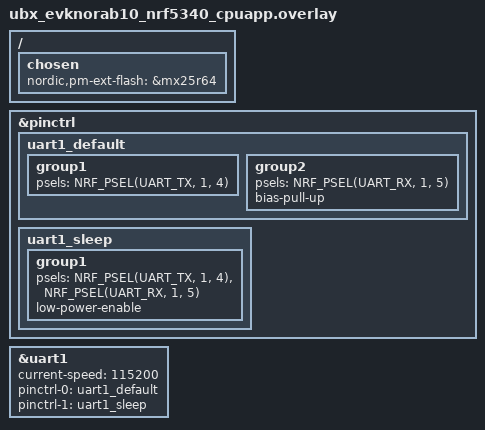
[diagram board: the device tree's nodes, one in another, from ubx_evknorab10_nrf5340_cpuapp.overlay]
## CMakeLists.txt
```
# SPDX-License-Identifier: Apache-2.0

cmake_minimum_required(VERSION 3.20.0)

find_package(Zephyr REQUIRED HINTS $ENV{ZEPHYR_BASE})
if (NOT SYSBUILD)
	message(WARNING
		" This is multi-image application that should be build using sysbuild.\n"
		" Add --sysbuild argument to west build command to prepare all the images.")
endif()
project(hrdfu)

target_sources(app PRIVATE src/main.c)
add_subdirectory(src/storage)
add_subdirectory(src/uart)
```

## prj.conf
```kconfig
CONFIG_BT=y
CONFIG_LOG=y
CONFIG_BT_SMP=y
CONFIG_BT_PERIPHERAL=y
CONFIG_BT_DIS=y
CONFIG_BT_DIS_PNP=n
CONFIG_BT_BAS=y
CONFIG_BT_HRS=y
CONFIG_BT_DEVICE_NAME="Zephyr Heartrate Sensor"
CONFIG_BT_DEVICE_APPEARANCE=833

CONFIG_SYSTEM_WORKQUEUE_STACK_SIZE=4096
CONFIG_MAIN_STACK_SIZE=8192

#-------------------------------------------------
CONFIG_MULTITHREADING=y
CONFIG_LOG_MODE_MINIMAL=n # former CONFIG_MODE_MINIMAL

CONFIG_LOG=y
CONFIG_PRINTK=y

# Config RTT logger
# CONFIG_CONSOLE=y
# CONFIG_UART_CONSOLE=n
# CONFIG_RTT_CONSOLE=y
# CONFIG_USE_SEGGER_RTT=y
# CONFIG_LOG_BACKEND_RTT=y
#----------------------------------------------------------
CONFIG_BOOTLOADER_MCUBOOT=y
CONFIG_NCS_SAMPLE_MCUMGR_BT_OTA_DFU=y

# #-------------------------------------------------
CONFIG_NRF53_UPGRADE_NETWORK_CORE=y
CONFIG_PM_EXTERNAL_FLASH_MCUBOOT_SECONDARY=y
CONFIG_UPDATEABLE_IMAGE_NUMBER=2
CONFIG_IMG_ERASE_PROGRESSIVELY=y

#-------------------------------------------------
CONFIG_SPI=y
CONFIG_NORDIC_QSPI_NOR=y
# Enable flash operations.
CONFIG_FLASH=y
CONFIG_FLASH_MAP=y
CONFIG_FLASH_PAGE_LAYOUT=y
CONFIG_STREAM_FLASH=y


# # Enable the LittleFS file system.
CONFIG_FILE_SYSTEM=y
CONFIG_FILE_SYSTEM_LITTLEFS=y

CONFIG_SERIAL=y
CONFIG_UART_INTERRUPT_DRIVEN=y
```

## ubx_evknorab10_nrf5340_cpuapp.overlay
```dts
// To get started, press Ctrl+Space to bring up the completion menu and view the available nodes.

// You can also use the buttons in the sidebar to perform actions on nodes.
// Actions currently available include:

// * Enabling / disabling the node
// * Adding the bus to a bus
// * Removing the node
// * Connecting ADC channels

// For more help, browse the DeviceTree documentation at https://docs.zephyrproject.org/latest/guides/dts/index.html
// You can also visit the nRF DeviceTree extension documentation at https://nrfconnect.github.io/vscode-nrf-connect/devicetree/nrfdevicetree.html
/ {

	chosen {
		nordic,pm-ext-flash = &mx25r64;
	};
};

&pinctrl {
	uart1_default: uart1_default {
		group1 {
			psels = <NRF_PSEL(UART_TX, 1, 4)>;
		};
		group2 {
			psels = <NRF_PSEL(UART_RX, 1, 5)>;
			bias-pull-up;
		};
	};

	uart1_sleep: uart1_sleep {
		group1 {
			psels = <NRF_PSEL(UART_TX, 1, 4)>,
				<NRF_PSEL(UART_RX, 1, 5)>;
			low-power-enable;
		};
	};
};

&uart1 {
	status = "okay";
	current-speed = <115200>;
	pinctrl-0 = <&uart1_default>;
	pinctrl-1 = <&uart1_sleep>;
	pinctrl-names = "default", "sleep";
};
```

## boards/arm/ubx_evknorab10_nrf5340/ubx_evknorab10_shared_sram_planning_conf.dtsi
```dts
/*
 * u-blox EVK-NORA-B10 board configuration
 *
 * Copyright (c) 2023 u-blox AG
 * SPDX-License-Identifier: Apache-2.0
 */

/* Default shared SRAM planning when building for nRF5340.
 * This file is included by both nRF5340 CPUAPP (Application MCU)
 * and nRF5340 CPUNET (Network MCU).
 * - 64 kB SRAM allocated as Shared memory (sram0_shared)
 * - Region defined after the image SRAM of Application MCU
 */

/ {
	chosen {
		/* shared memory reserved for the inter-processor communication */
		zephyr,ipc_shm = &sram0_shared;
	};

	reserved-memory {
		#address-cells = <1>;
		#size-cells = <1>;
		ranges;

		// /delete-node/ memory@20070000 ;
		sram0_shared: memory@20070000 {
		  reg = <0x20070000 0xFF00>;
		};
		sram_netcore_fw_data: memory@2007FF00 {
		  reg = <0x2007FF00 0x100>;
		};
	};
	aliases {
		sramnetcorefwdata = &sram_netcore_fw_data;
	  };
};
```

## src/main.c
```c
/**
 * @file main.c
 * @brief Application main entry point for Host Receive Device Firmware Update (HRDFU)
 *
 * This application demonstrates a Bluetooth Low Energy OTA firmware update mechanism for
 * the nRF5340 dual-core SoC. It supports updates for both the application and network cores.
 */

/*
 * Copyright (c) 2015-2016 Intel Corporation
 *
 * SPDX-License-Identifier: Apache-2.0
 */

#include <zephyr/types.h>
#include <stddef.h>
#include <string.h>
#include <errno.h>
#include <zephyr/sys/printk.h>
#include <zephyr/sys/byteorder.h>
#include <zephyr/kernel.h>

#include <zephyr/bluetooth/bluetooth.h>
#include <zephyr/bluetooth/hci.h>
#include <zephyr/bluetooth/conn.h>
#include <zephyr/bluetooth/uuid.h>
#include <zephyr/bluetooth/gatt.h>
#include <zephyr/bluetooth/services/bas.h>
#include <zephyr/bluetooth/services/hrs.h>

#include <zephyr/storage/flash_map.h>
#include <zephyr/dfu/flash_img.h>

#include "useruart.h"
#include "storage.h"

/**
 * @brief Bluetooth advertising data - defines services advertised by the device
 */
static const struct bt_data ad[] = {
    BT_DATA_BYTES(BT_DATA_FLAGS, (BT_LE_AD_GENERAL | BT_LE_AD_NO_BREDR)),
    BT_DATA_BYTES(BT_DATA_UUID16_ALL,
              BT_UUID_16_ENCODE(BT_UUID_HRS_VAL),
              BT_UUID_16_ENCODE(BT_UUID_BAS_VAL),
              BT_UUID_16_ENCODE(BT_UUID_DIS_VAL))
};

/**
 * @brief Bluetooth scan response data - contains custom UUID for DFU service
 */
static const struct bt_data sd[] = {
    BT_DATA_BYTES(BT_DATA_UUID128_ALL,
              0x84, 0xaa, 0x60, 0x74, 0x52, 0x8a, 0x8b, 0x86,
              0xd3, 0x4c, 0xb7, 0x1d, 0x1d, 0xdc, 0x53, 0x8d),
};

/** @brief Select target core for firmware update: 1 for network core, 0 for app core */
#define TESTING_NET_CORE_DFU 1

/** @brief Flash image context for firmware update operations */
struct flash_img_context flash_ctx;

/**
 * @brief Callback for Bluetooth connection events
 *
 * Called when a device connects to this device over Bluetooth
 *
 * @param conn Pointer to the connection that was established
 * @param err Error code (0 for successful connection)
 */
static void connected(struct bt_conn *conn, uint8_t err)
{
    if (err) {
        printk("Connection failed (err 0x%02x)\n", err);
    } else {
        printk("Connected\n");
    }
}

/**
 * @brief Callback for Bluetooth disconnection events
 *
 * Called when a device disconnects from this device
 *
 * @param conn Pointer to the connection that was terminated
 * @param reason Reason code for the disconnection
 */
static void disconnected(struct bt_conn *conn, uint8_t reason)
{
    printk("Disconnected (reason 0x%02x)\n", reason);
}

/** @brief Define Bluetooth connection callbacks */
BT_CONN_CB_DEFINE(conn_callbacks) = {
    .connected = connected,
    .disconnected = disconnected,
};

/**
 * @brief Initialize and start Bluetooth advertising
 *
 * Called once Bluetooth stack is fully initialized
 */
static void bt_ready(void)
{
    int err;

    printk("Bluetooth initialized\n");

    err = bt_le_adv_start(BT_LE_ADV_CONN_NAME, ad, ARRAY_SIZE(ad), sd, ARRAY_SIZE(sd));
    if (err) {
        printk("Advertising failed to start (err %d)\n", err);
        return;
    }

    printk("Advertising successfully started\n");
}

/**
 * @brief Callback for authentication cancellation events
 *
 * Called when a pairing/authentication process is cancelled
 *
 * @param conn Pointer to the connection for which authentication was cancelled
 */
static void auth_cancel(struct bt_conn *conn)
{
    char addr[BT_ADDR_LE_STR_LEN];

    bt_addr_le_to_str(bt_conn_get_dst(conn), addr, sizeof(addr));

    printk("Pairing cancelled: %s\n", addr);
}

/** @brief Authentication callbacks structure */
static struct bt_conn_auth_cb auth_cb_display = {
    .cancel = auth_cancel,
};

/**
 * @brief Update and notify battery service level
 *
 * Simulates decreasing battery level and notifies subscribers
 */
static void bas_notify(void)
{
    uint8_t battery_level = bt_bas_get_battery_level();

    battery_level--;

    if (!battery_level) {
        battery_level = 100U;
    }

    bt_bas_set_battery_level(battery_level);
}

/**
 * @brief Update and notify heart rate service
 *
 * Simulates heart rate measurements and notifies subscribers
 */
static void hrs_notify(void)
{
    static uint8_t heartrate = 90U;

    /* Heartrate measurements simulation */
    heartrate++;
    if (heartrate == 160U) {
        heartrate = 90U;
    }

    bt_hrs_notify(heartrate);
}

/**
 * @brief Structure to hold network core firmware version information
 */
typedef struct
{
    uint8_t Major;
    uint8_t Minor;
    uint8_t Build;
} netCoreFwVersion_Struct;

/** @brief ACK response byte to indicate successful operation */
uint8_t ACK_BYTE = 0x06;

/** @brief NACK response byte to indicate failed operation */
uint8_t NACK_BYTE = 0x15;

/**
 * @brief Main application entry point
 *
 * Initializes Bluetooth, UART communication and handles the firmware update process
 *
 * @return 0 on successful completion (never reached in normal operation)
 */
int main(void)
{
    int err;
    printk("Starting DFU Test ...\n");

    // Initialize Bluetooth stack
    err = bt_enable(NULL);
    if (err) {
        printk("Bluetooth init failed (err %d)\n", err);
        return 0;
    }

    bt_ready();

    bt_conn_auth_cb_register(&auth_cb_display);

    /* Implement notification. At the moment there is no suitable way
     * of starting delayed work so we do it here
     */

    // Initialize UART for receiving firmware updates
    printk("serial init: %d\r\n", init_serial_comms_handler());

    // Read network core firmware version from shared memory
    netCoreFwVersion_Struct *netCoreFwVersion= NULL;
    netCoreFwVersion = (netCoreFwVersion_Struct*)DT_REG_ADDR(DT_ALIAS(sramnetcorefwdata));
    k_sleep(K_SECONDS(5));
    printk("netcore: %d.%d.%d\r\n", netCoreFwVersion->Major, netCoreFwVersion->Minor, netCoreFwVersion->Build);

    // Track total bytes written during firmware update
    uint32_t TotalBytesWritten = 0;
    
    // Main application loop
    while (1) {
        k_sleep(K_MSEC(5));

        // Check for new UART data by detecting idle time after receiving data
        bool flush = false;
        if ((k_uptime_get_32() - lastInterruptTime) > 100 && totalBytesReceived > 0)
        {
            // Verify if received data forms a valid packet
            err = verifyPacket();
            
            // Handle firmware data packet (type 0x03)
            if(err == 0x03)
            {
                // Set flush flag for last data packet in a sequence
                if (OTADataSize != MAX_PACKET_SIZE)
                {
                    printk("flushing\r\n");
                    flush = true;
                }
                
                // Write firmware data to flash memory
                if(WriteFwDataToFlash(&flash_ctx, OTABuffer, OTADataSize, flush) == 0)
                {
                    TotalBytesWritten += OTADataSize;
                    printk("TotalBytesWritten: %d\r\n", TotalBytesWritten);
                    ResetRxBuffer();
                    SendUartData(&ACK_BYTE, 1);  // Acknowledge successful write
                }
                else
                {
                    // Handle flash write failure
                    ResetRxBuffer();
                    SendUartData(&NACK_BYTE, 1);  // Send negative acknowledgement
                }
            }
            // Handle file size information packet (type 0x02)
            else if (err == 0x02)
            {
                ResetRxBuffer();

                // Initialize flash context for appropriate core
                #if TESTING_NET_CORE_DFU == 1
                InitFwDataWrite(&flash_ctx, NET_CORE_DFU_PARTITION);
                #else
                InitFwDataWrite(&flash_ctx, APP_CORE_DFU_PARTITION);
                #endif
                TotalBytesWritten = 0;

                SendUartData(&ACK_BYTE, 1);  // Acknowledge initialization
            }
            else
            {
                // Invalid packet received
                SendUartData(&NACK_BYTE, 1);
            }
        }

        // Check if firmware transfer is complete
        if ((TotalBytesWritten == FileSize) && (FileSize != 0) && (TotalBytesWritten != 0))
        {
            printk("File transfer complete ... %d/%d\r\n", TotalBytesWritten, FileSize);
            
            // Set MCUboot flag to perform update on next boot
            #if TESTING_NET_CORE_DFU == 1
            SetFwUpdatMcuBootFlag(NET_CORE_DFU_PARTITION);
            #else
            SetFwUpdatMcuBootFlag(APP_CORE_DFU_PARTITION);
            #endif

            // Wait briefly then reset the system to apply the update
            k_sleep(K_SECONDS(5));
            NVIC_SystemReset();
        }
    }
    return 0;  // Never reached
}
```
